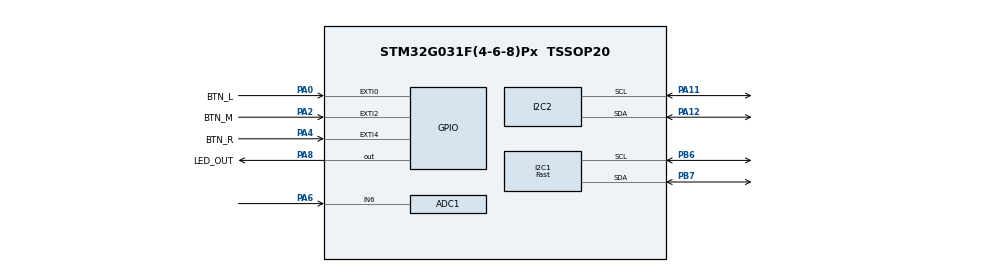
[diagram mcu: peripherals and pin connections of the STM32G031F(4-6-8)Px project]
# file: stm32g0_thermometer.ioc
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ADC1.Channel-0\#ChannelRegularConversion=ADC_CHANNEL_6
ADC1.Channel-2\#ChannelRegularConversion=ADC_CHANNEL_VREFINT
ADC1.ClockPrescaler=ADC_CLOCK_ASYNC_DIV32
ADC1.ContinuousConvMode=ENABLE
ADC1.DMAContinuousRequests=ENABLE
ADC1.EOCSelection=ADC_EOC_SEQ_CONV
ADC1.NbrOfConversion=2
ADC1.NbrOfConversionFlag=1
ADC1.Overrun=ADC_OVR_DATA_OVERWRITTEN
ADC1.Rank-0\#ChannelRegularConversion=1
ADC1.Rank-2\#ChannelRegularConversion=2
ADC1.SamplingTime-0\#ChannelRegularConversion=ADC_SAMPLINGTIME_COMMON_1
ADC1.SamplingTime-2\#ChannelRegularConversion=ADC_SAMPLINGTIME_COMMON_1
ADC1.SamplingTimeCommon1=ADC_SAMPLETIME_160CYCLES_5
ADC1.SamplingTimeCommon2=ADC_SAMPLETIME_160CYCLES_5
ADC1.SelectedChannel=ADC_CHANNEL_6|ADC_CHANNEL_VREFINT
ADC1.master=1
Dma.ADC1.1.Direction=DMA_PERIPH_TO_MEMORY
Dma.ADC1.1.EventEnable=DISABLE
Dma.ADC1.1.Instance=DMA1_Channel2
Dma.ADC1.1.MemDataAlignment=DMA_MDATAALIGN_HALFWORD
Dma.ADC1.1.MemInc=DMA_MINC_ENABLE
Dma.ADC1.1.Mode=DMA_CIRCULAR
Dma.ADC1.1.PeriphDataAlignment=DMA_PDATAALIGN_HALFWORD
Dma.ADC1.1.PeriphInc=DMA_PINC_DISABLE
Dma.ADC1.1.Polarity=HAL_DMAMUX_REQ_GEN_RISING
Dma.ADC1.1.Priority=DMA_PRIORITY_LOW
Dma.ADC1.1.RequestNumber=1
Dma.ADC1.1.SignalID=NONE
Dma.ADC1.1.SyncEnable=DISABLE
Dma.ADC1.1.SyncPolarity=HAL_DMAMUX_SYNC_NO_EVENT
Dma.ADC1.1.SyncRequestNumber=1
Dma.ADC1.1.SyncSignalID=NONE
Dma.I2C1_TX.0.Direction=DMA_MEMORY_TO_PERIPH
Dma.I2C1_TX.0.EventEnable=DISABLE
Dma.I2C1_TX.0.Instance=DMA1_Channel1
Dma.I2C1_TX.0.MemDataAlignment=DMA_MDATAALIGN_BYTE
Dma.I2C1_TX.0.MemInc=DMA_MINC_ENABLE
Dma.I2C1_TX.0.Mode=DMA_NORMAL
Dma.I2C1_TX.0.PeriphDataAlignment=DMA_PDATAALIGN_BYTE
Dma.I2C1_TX.0.PeriphInc=DMA_PINC_DISABLE
Dma.I2C1_TX.0.Polarity=HAL_DMAMUX_REQ_GEN_RISING
Dma.I2C1_TX.0.Priority=DMA_PRIORITY_HIGH
Dma.I2C1_TX.0.RequestNumber=1
Dma.I2C1_TX.0.SignalID=NONE
Dma.I2C1_TX.0.SyncEnable=DISABLE
Dma.I2C1_TX.0.SyncPolarity=HAL_DMAMUX_SYNC_NO_EVENT
Dma.I2C1_TX.0.SyncRequestNumber=1
Dma.I2C1_TX.0.SyncSignalID=NONE
Dma.I2C2_RX.3.Direction=DMA_PERIPH_TO_MEMORY
Dma.I2C2_RX.3.EventEnable=DISABLE
Dma.I2C2_RX.3.Instance=DMA1_Channel4
Dma.I2C2_RX.3.MemDataAlignment=DMA_MDATAALIGN_BYTE
Dma.I2C2_RX.3.MemInc=DMA_MINC_ENABLE
Dma.I2C2_RX.3.Mode=DMA_NORMAL
Dma.I2C2_RX.3.PeriphDataAlignment=DMA_PDATAALIGN_BYTE
Dma.I2C2_RX.3.PeriphInc=DMA_PINC_DISABLE
Dma.I2C2_RX.3.Polarity=HAL_DMAMUX_REQ_GEN_RISING
Dma.I2C2_RX.3.Priority=DMA_PRIORITY_LOW
Dma.I2C2_RX.3.RequestNumber=1
Dma.I2C2_RX.3.SignalID=NONE
Dma.I2C2_RX.3.SyncEnable=DISABLE
Dma.I2C2_RX.3.SyncPolarity=HAL_DMAMUX_SYNC_NO_EVENT
Dma.I2C2_RX.3.SyncRequestNumber=1
Dma.I2C2_RX.3.SyncSignalID=NONE
Dma.I2C2_TX.2.Direction=DMA_MEMORY_TO_PERIPH
Dma.I2C2_TX.2.EventEnable=DISABLE
Dma.I2C2_TX.2.Instance=DMA1_Channel3
Dma.I2C2_TX.2.MemDataAlignment=DMA_MDATAALIGN_BYTE
Dma.I2C2_TX.2.MemInc=DMA_MINC_ENABLE
Dma.I2C2_TX.2.Mode=DMA_NORMAL
Dma.I2C2_TX.2.PeriphDataAlignment=DMA_PDATAALIGN_BYTE
Dma.I2C2_TX.2.PeriphInc=DMA_PINC_DISABLE
Dma.I2C2_TX.2.Polarity=HAL_DMAMUX_REQ_GEN_RISING
Dma.I2C2_TX.2.Priority=DMA_PRIORITY_LOW
Dma.I2C2_TX.2.RequestNumber=1
Dma.I2C2_TX.2.SignalID=NONE
Dma.I2C2_TX.2.SyncEnable=DISABLE
Dma.I2C2_TX.2.SyncPolarity=HAL_DMAMUX_SYNC_NO_EVENT
Dma.I2C2_TX.2.SyncRequestNumber=1
Dma.I2C2_TX.2.SyncSignalID=NONE
Dma.Request0=I2C1_TX
Dma.Request1=ADC1
Dma.Request2=I2C2_TX
Dma.Request3=I2C2_RX
I2C1.I2C_Speed_Mode=I2C_Fast
I2C1.Speed=400
I2C1.Timing=0x00C12166
I2C2.Timing=0x10B17DB5
Mcu.Family=STM32G0
Mcu.Name=STM32G031F(4-6-8)Px
Mcu.Package=TSSOP20
NVIC.DMA1_Ch4_5_DMAMUX1_OVR_IRQn=true\:0\:0\:false\:false\:true\:false\:true\:true
NVIC.DMA1_Channel1_IRQn=true\:0\:0\:false\:false\:true\:false\:true\:true
NVIC.DMA1_Channel2_3_IRQn=true\:0\:0\:false\:false\:true\:false\:true\:true
NVIC.EXTI0_1_IRQn=true\:0\:0\:false\:false\:true\:true\:true\:true
NVIC.EXTI2_3_IRQn=true\:0\:0\:false\:false\:true\:true\:true\:true
NVIC.EXTI4_15_IRQn=true\:0\:0\:false\:false\:true\:true\:true\:true
PA0.GPIO_Label=BTN_L
PA0.GPIO_ModeDefaultEXTI=GPIO_MODE_IT_FALLING
PA0.Signal=GPXTI0
PA11\ [PA9].Mode=I2C
PA11\ [PA9].Signal=I2C2_SCL
PA12\ [PA10].Mode=I2C
PA12\ [PA10].Signal=I2C2_SDA
PA13.Mode=Serial_Wire
PA13.Signal=SYS_SWDIO
PA14-BOOT0.Mode=Serial_Wire
PA14-BOOT0.Signal=SYS_SWCLK
PA14-BOOT0__PA15.StandardMode=true
PA2.GPIO_Label=BTN_M
PA2.GPIO_ModeDefaultEXTI=GPIO_MODE_IT_FALLING
PA2.Signal=GPXTI2
PA4.GPIO_Label=BTN_R
PA4.GPIO_ModeDefaultEXTI=GPIO_MODE_IT_FALLING
PA4.Signal=GPXTI4
PA6.Mode=IN6
PA6.Signal=ADC1_IN6
PA8.GPIO_Label=LED_OUT
PA8.Signal=GPIO_Output
PB0__PB1__PB2__PA8.StandardMode=true
PB3__PB4__PB5__PB6.StandardMode=true
PB6.GPIO_Pu=GPIO_NOPULL
PB6.Mode=I2C
PB6.Signal=I2C1_SCL
PB7.GPIO_Pu=GPIO_NOPULL
PB7.Mode=I2C
PB7.Signal=I2C1_SDA
PB7__PB8.StandardMode=true
PC14-OSC32_IN\ (PC14).Mode=LSE-External-Oscillator
PC14-OSC32_IN\ (PC14).Signal=RCC_OSC32_IN
PC14-OSC32_IN\ (PC14)__PB9.StandardMode=true
PC15-OSC32_OUT\ (PC15).Mode=LSE-External-Oscillator
PC15-OSC32_OUT\ (PC15).Signal=RCC_OSC32_OUT
ProjectManager.HeapSize=0x200
ProjectManager.StackSize=0x400
ProjectManager.TargetToolchain=STM32CubeIDE
RCC.ADCFreq_Value=64000000
RCC.AHBFreq_Value=64000000
RCC.CortexFreq_Value=64000000
RCC.EXTERNAL_CLOCK_VALUE=12288000
RCC.HCLKFreq_Value=64000000
RCC.HSE_VALUE=8000000
RCC.HSI_VALUE=16000000
RCC.PLLP=RCC_PLLP_DIV4
RCC.SYSCLKFreq_VALUE=64000000
RCC.SYSCLKSource=RCC_SYSCLKSOURCE_PLLCLK
RCC.VCOOutputFreq_Value=128000000
RTC.Date=6
RTC.Format=RTC_FORMAT_BIN
RTC.Hours=12
RTC.Minutes=12
RTC.Year=24
VP_ADC1_Vref_Input.Mode=IN-Vrefint
VP_RTC_VS_RTC_Activate.Mode=RTC_Enabled
VP_RTC_VS_RTC_Calendar.Mode=RTC_Calendar
board=custom

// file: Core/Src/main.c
/* USER CODE BEGIN Header */
/**
  ******************************************************************************
  * @file           : main.c
  * @brief          : Main program body
  ******************************************************************************
  * @attention
  *
  * Copyright (c) 2024 STMicroelectronics.
  * All rights reserved.
  *
  * This software is licensed under terms that can be found in the LICENSE file
  * in the root directory of this software component.
  * If no LICENSE file comes with this software, it is provided AS-IS.
  *
  ******************************************************************************
  */
/* USER CODE END Header */
#include "main.h"
#include "adc.h"
#include "dma.h"
#include "i2c.h"
#include "rtc.h"
#include "gpio.h"

/* USER CODE BEGIN Includes */
#include "ssd1306.h"
#include "ctrl_rtc.h"
#include "ctrl_measure.h"
#include "ctrl_device.h"
#include "ctrl_power.h"

/* USER CODE END Includes */

void SystemClock_Config(void);

int main(void)
{

  /* MCU Configuration--------------------------------------------------------*/

  /* Reset of all peripherals, Initializes the Flash interface and the Systick. */
  LL_APB2_GRP1_EnableClock(LL_APB2_GRP1_PERIPH_SYSCFG);
  LL_APB1_GRP1_EnableClock(LL_APB1_GRP1_PERIPH_PWR);

  /* SysTick_IRQn interrupt configuration */
  NVIC_SetPriority(SysTick_IRQn, 3);

  /* Configure the system clock */
  SystemClock_Config();

  /* Initialize all configured peripherals */
  MX_GPIO_Init();
  MX_DMA_Init();
  MX_I2C1_Init();
  MX_ADC1_Init();
  MX_RTC_Init();
  MX_I2C2_Init();
  /* USER CODE BEGIN 2 */
  ssd1306_Init(I2C1);
  rtc_init();
  ctrl_measure_init();
  //SSD1306_ON(I2C1);
  LL_mDelay(100);
  LL_GPIO_TogglePin(LED_OUT_GPIO_Port, LED_OUT_Pin);
  ctrl_power_init(&CTRLpower);

  //SSD1306_Clear (I2C1);
  /* USER CODE END 2 */

  /* Infinite loop */
  /* USER CODE BEGIN WHILE */
  while (1)
  {
	  //1st pixel for oled is at 28,24 position
	  ctrl_device(&CTRLdevice);
//	  LL_mDelay(500);

    /* USER CODE END WHILE */

  }
}

void SystemClock_Config(void)
{
  LL_FLASH_SetLatency(LL_FLASH_LATENCY_2);
  while(LL_FLASH_GetLatency() != LL_FLASH_LATENCY_2)
  {
  }

  /* HSI configuration and activation */
  LL_RCC_HSI_Enable();
  while(LL_RCC_HSI_IsReady() != 1)
  {
  }

  /* LSI configuration and activation */
  LL_RCC_LSI_Enable();
  while(LL_RCC_LSI_IsReady() != 1)
  {
  }

  LL_PWR_EnableBkUpAccess();
  /* Main PLL configuration and activation */
  LL_RCC_PLL_ConfigDomain_SYS(LL_RCC_PLLSOURCE_HSI, LL_RCC_PLLM_DIV_1, 8, LL_RCC_PLLR_DIV_2);
  LL_RCC_PLL_Enable();
  LL_RCC_PLL_EnableDomain_SYS();
  while(LL_RCC_PLL_IsReady() != 1)
  {
  }

  /* Set AHB prescaler*/
  LL_RCC_SetAHBPrescaler(LL_RCC_SYSCLK_DIV_1);

  /* Sysclk activation on the main PLL */
  LL_RCC_SetSysClkSource(LL_RCC_SYS_CLKSOURCE_PLL);
  while(LL_RCC_GetSysClkSource() != LL_RCC_SYS_CLKSOURCE_STATUS_PLL)
  {
  }

  /* Set APB1 prescaler*/
  LL_RCC_SetAPB1Prescaler(LL_RCC_APB1_DIV_1);

  LL_Init1msTick(64000000);

  /* Update CMSIS variable (which can be updated also through SystemCoreClockUpdate function) */
  LL_SetSystemCoreClock(64000000);
}

void Error_Handler(void)
{
  __disable_irq();
  while (1)
  {
  }
}
